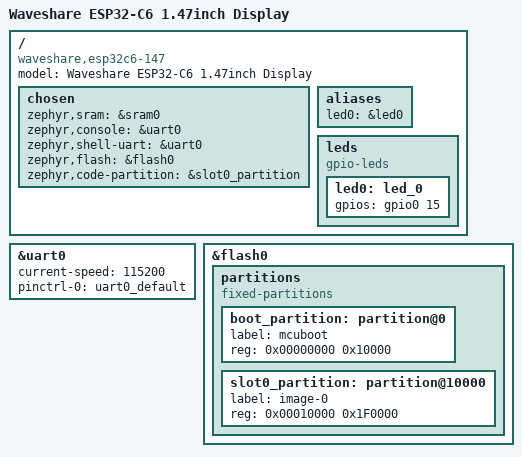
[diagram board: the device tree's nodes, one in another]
/dts-v1/;

#include <espressif/esp32c6/esp32c6_wroom_n4.dtsi>
#include "waveshare_esp32c6_147-pinctrl.dtsi"

/ {
	model = "Waveshare ESP32-C6 1.47inch Display";
	compatible = "waveshare,esp32c6-147";

	chosen {
		zephyr,sram = &sram0;
		zephyr,console = &uart0;
		zephyr,shell-uart = &uart0;
		zephyr,flash = &flash0;
		zephyr,code-partition = &slot0_partition;
	};

	aliases {
		led0 = &led0;
	};

	leds {
		compatible = "gpio-leds";
		led0: led_0 {
			gpios = <&gpio0 15 GPIO_ACTIVE_HIGH>;
		};
	};
};

&uart0 {
	status = "okay";
	current-speed = <115200>;
	pinctrl-0 = <&uart0_default>;
	pinctrl-names = "default";
};

&flash0 {
	partitions {
		compatible = "fixed-partitions";
		#address-cells = <1>;
		#size-cells = <1>;

		boot_partition: partition@0 {
			label = "mcuboot";
			reg = <0x00000000 0x10000>;
		};

		slot0_partition: partition@10000 {
			label = "image-0";
			reg = <0x00010000 0x1F0000>;
		};
	};
};
